# R7FA2L1AB register map
Vendor: Renesas Electronics Corporation; Series: RA2L1; File version: 1.60.00
CPU: CM23 r1p0, little endian, MPU, no FPU, VTOR, 2 interrupt priority bits, 32 interrupts
Registers are 8-bit, read-write, reset 0x0 unless marked. A register's access mark holds for its fields unless they carry their own. Offsets are from the block's base; [hi:lo] are bit positions; {n}, {i} and the like mark numbered series; 'fields as' and 'values as' point back to an identical list; <NAME> marks a mode.

## GPT320 — General PWM 32-bit Timer 0
Base 0x40078000
Same registers: GPT321 0x40078100, GPT322 0x40078200, GPT323 0x40078300
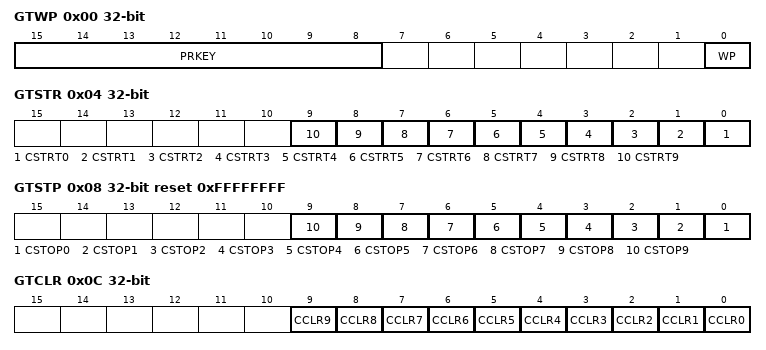
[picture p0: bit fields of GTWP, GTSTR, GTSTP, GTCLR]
0x00 GTWP 32-bit — General PWM Timer Write-Protection Register
  [15:8] PRKEY wo — GTWP Key Code
  [0] WP — Register Write Disable
    0=Write to the register enabled; 1=Write to the register disabled
0x04 GTSTR 32-bit — General PWM Timer Software Start Register
  [all] fields
    0=GTCNT counter not start; 1=GTCNT counter start
  [n] CSTRT{n} (n=0..9) — Channel n GTCNT Count Start (n : the same as bit position value)
0x08 GTSTP 32-bit reset 0xFFFFFFFF — General PWM Timer Software Stop Register
  [all] fields
    0=GTCNT counter not stop; 1=GTCNT counter stop
  [n] CSTOP{n} (n=0..9) — Channel n GTCNT Count Stop (n : the same as bit position value)
0x0C GTCLR 32-bit wo — General PWM Timer Software Clear Register
  [all] fields
    0=GTCNT counter is not cleared; 1=GTCNT counter is cleared
  [n] CCLR{n} (n=0..9) — Channel n GTCNT Count Clear (n : the same as bit position value)
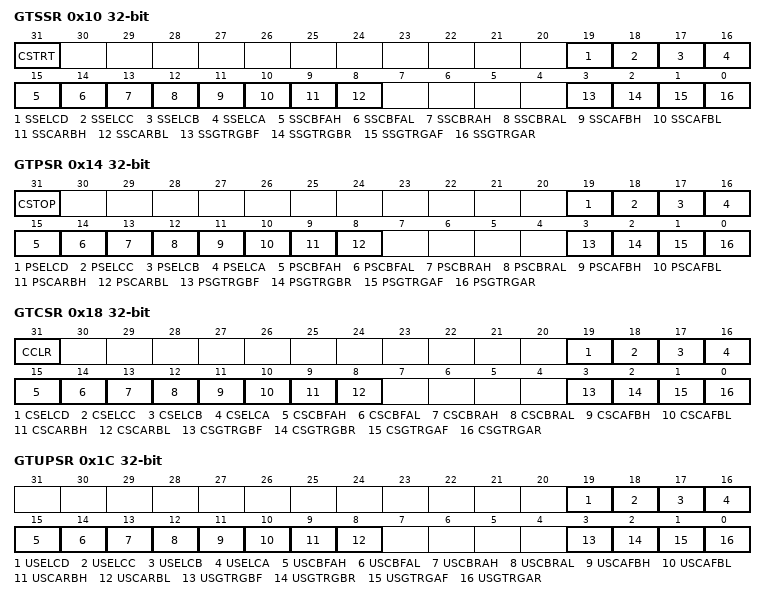
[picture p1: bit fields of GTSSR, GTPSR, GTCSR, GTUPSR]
0x10 GTSSR 32-bit — General PWM Timer Start Source Select Register
  [31] CSTRT — Software Source Counter Start Enable
    0=Counter start disabled by the GTSTR register; 1=Counter start enabled by the GTSTR register
  [19] SSELCD — ELC_GPTD Event Source Counter Start Enable
    0=Counter start disabled at the ELC_GPTD input; 1=Counter start enabled at the ELC_GPTD input
  [18] SSELCC — ELC_GPTC Event Source Counter Start Enable
    0=Counter start disabled at the ELC_GPTC input; 1=Counter start enabled at the ELC_GPTC input
  [17] SSELCB — ELC_GPTB Event Source Counter Start Enable
    0=Counter start disabled at the ELC_GPTB input; 1=Counter start enabled at the ELC_GPTB input
  [16] SSELCA — ELC_GPTA Event Source Counter Start Enable
    0=Counter start disabled at the ELC_GPTA input; 1=Counter start enabled at the ELC_GPTA input
  [15] SSCBFAH — GTIOCnB Pin Falling Input during GTIOCnA Value High Source Counter Start Enable
    0=Counter start disabled on the falling edge of GTIOCnB input when GTIOCnA input is 1; 1=Counter start enabled on the falling edge of GTIOCnB input when GTIOCnA input is 1
  [14] SSCBFAL — GTIOCnB Pin Falling Input during GTIOCnA Value Low Source Counter Start Enable
    0=Counter start disabled on the falling edge of GTIOCnB input when GTIOCnA input is 0; 1=Counter start enabled on the falling edge of GTIOCnB input when GTIOCnA input is 0
  [13] SSCBRAH — GTIOCnB Pin Rising Input during GTIOCnA Value High Source Counter Start Enable
    0=Counter start disabled on the rising edge of GTIOCnB input when GTIOCnA input is 1; 1=Counter start enabled on the rising edge of GTIOCnB input when GTIOCnA input is 1
  [12] SSCBRAL — GTIOCnB Pin Rising Input during GTIOCnA Value Low Source Counter Start Enable
    0=Counter start disabled on the rising edge of GTIOCnB input when GTIOCnA input is 0; 1=Counter start enabled on the rising edge of GTIOCnB input when GTIOCnA input is 0
  [11] SSCAFBH — GTIOCnA Pin Falling Input during GTIOCnB Value High Source Counter Start Enable
    0=Counter start disabled on the falling edge of GTIOCnA input when GTIOCnB input is 1; 1=Counter start enabled on the falling edge of GTIOCnA input when GTIOCnB input is 1
  [10] SSCAFBL — GTIOCnA Pin Falling Input during GTIOCnB Value Low Source Counter Start Enable
    0=Counter start disabled on the falling edge of GTIOCnA input when GTIOCnB input is 0; 1=Counter start enabled on the falling edge of GTIOCnA input when GTIOCnB input is 0
  [9] SSCARBH — GTIOCnA Pin Rising Input during GTIOCnB Value High Source Counter Start Enable
    0=Counter start disabled on the rising edge of GTIOCnA input when GTIOCnB input is 1; 1=Counter start enabled on the rising edge of GTIOCnA input when GTIOCnB input is 1
  [8] SSCARBL — GTIOCnA Pin Rising Input during GTIOCnB Value Low Source Counter Start Enable
    0=Counter start disabled on the rising edge of GTIOCnA input when GTIOCnB input is 0; 1=Counter start enabled on the rising edge of GTIOCnA input when GTIOCnB input is 0
  [3] SSGTRGBF — GTETRGB Pin Falling Input Source Counter Start Enable
    0=Counter start disabled on the falling edge of GTETRGB input; 1=Counter start enabled on the falling edge of GTETRGB input
  [2] SSGTRGBR — GTETRGB Pin Rising Input Source Counter Start Enable
    0=Counter start disabled on the rising edge of GTETRGB input; 1=Counter start enabled on the rising edge of GTETRGB input
  [1] SSGTRGAF — GTETRGA Pin Falling Input Source Counter Start Enable
    0=Counter start disabled on the falling edge of GTETRGA input; 1=Counter start enabled on the falling edge of GTETRGA input
  [0] SSGTRGAR — GTETRGA Pin Rising Input Source Counter Start Enable
    0=Counter start disabled on the rising edge of GTETRGA input; 1=Counter start enabled on the rising edge of GTETRGA input
0x14 GTPSR 32-bit — General PWM Timer Stop Source Select Register
  [31] CSTOP — Software Source Counter Stop Enable
    0=Counter stop disabled by the GTSTP register; 1=Counter stop enabled by the GTSTP register
  [19] PSELCD — ELC_GPTD Event Source Counter Stop Enable
    0=Counter stop disabled at the ELC_GPTD input; 1=Counter stop enabled at the ELC_GPTD input
  [18] PSELCC — ELC_GPTC Event Source Counter Stop Enable
    0=Counter stop disabled at the ELC_GPTC input; 1=Counter stop enabled at the ELC_GPTC input
  [17] PSELCB — ELC_GPTB Event Source Counter Stop Enable
    0=Counter stop disabled at the ELC_GPTB input; 1=Counter stop enabled at the ELC_GPTB input
  [16] PSELCA — ELC_GPTA Event Source Counter Stop Enable
    0=Counter stop disabled at the ELC_GPTA input; 1=Counter stop enabled at the ELC_GPTA input
  [15] PSCBFAH — GTIOCnB Pin Falling Input during GTIOCnA Value High Source Counter Stop Enable
    0=Counter stop disabled on the falling edge of GTIOCnB input when GTIOCnA input is 1; 1=Counter stop enabled on the falling edge of GTIOCnB input when GTIOCnA input is 1
  [14] PSCBFAL — GTIOCnB Pin Falling Input during GTIOCnA Value Low Source Counter Stop Enable
    0=Counter stop disabled on the falling edge of GTIOCnB input when GTIOCnA input is 0; 1=Counter stop enabled on the falling edge of GTIOCnB input when GTIOCnA input is 0
  [13] PSCBRAH — GTIOCnB Pin Rising Input during GTIOCnA Value High Source Counter Stop Enable
    0=Counter stop disabled on the rising edge of GTIOCnB input when GTIOCnA input is 1; 1=Counter stop enabled on the rising edge of GTIOCnB input when GTIOCnA input is 1
  [12] PSCBRAL — GTIOCnB Pin Rising Input during GTIOCnA Value Low Source Counter Stop Enable
    0=Counter stop disabled on the rising edge of GTIOCnB input when GTIOCnA input is 0; 1=Counter stop enabled on the rising edge of GTIOCnB input when GTIOCnA input is 0
  [11] PSCAFBH — GTIOCnA Pin Falling Input during GTIOCnB Value High Source Counter Stop Enable
    0=Counter stop disabled on the falling edge of GTIOCnA input when GTIOCnB input is 1; 1=Counter stop enabled on the falling edge of GTIOCnA input when GTIOCnB input is 1
  [10] PSCAFBL — GTIOCnA Pin Falling Input during GTIOCnB Value Low Source Counter Stop Enable
    0=Counter stop disabled on the falling edge of GTIOCnA input when GTIOCnB input is 0; 1=Counter stop enabled on the falling edge of GTIOCnA input when GTIOCnB input is 0
  [9] PSCARBH — GTIOCnA Pin Rising Input during GTIOCnB Value High Source Counter Stop Enable
    0=Counter stop disabled on the rising edge of GTIOCnA input when GTIOCnB input is 1; 1=Counter stop enabled on the rising edge of GTIOCnA input when GTIOCnB input is 1
  [8] PSCARBL — GTIOCnA Pin Rising Input during GTIOCnB Value Low Source Counter Stop Enable
    0=Counter stop disabled on the rising edge of GTIOCnA input when GTIOCnB input is 0; 1=Counter stop enabled on the rising edge of GTIOCnA input when GTIOCnB input is 0
  [3] PSGTRGBF — GTETRGB Pin Falling Input Source Counter Stop Enable
    0=Counter stop disabled on the falling edge of GTETRGB input; 1=Counter stop enabled on the falling edge of GTETRGB input
  [2] PSGTRGBR — GTETRGB Pin Rising Input Source Counter Stop Enable
    0=Counter stop disabled on the rising edge of GTETRGB input; 1=Counter stop enabled on the rising edge of GTETRGB input
  [1] PSGTRGAF — GTETRGA Pin Falling Input Source Counter Stop Enable
    0=Counter stop disabled on the falling edge of GTETRGA input; 1=Counter stop enabled on the falling edge of GTETRGA input
  [0] PSGTRGAR — GTETRGA Pin Rising Input Source Counter Stop Enable
    0=Counter stop disabled on the rising edge of GTETRGA input; 1=Counter stop enabled on the rising edge of GTETRGA input
0x18 GTCSR 32-bit — General PWM Timer Clear Source Select Register
  [31] CCLR — Software Source Counter Clear Enable
    0=Counter clear disabled by the GTCLR register; 1=Counter clear enabled by the GTCLR register
  [19] CSELCD — ELC_GPTD Event Source Counter Clear Enable
    0=Counter clear disabled at the ELC_GPTD input; 1=Counter clear enabled at the ELC_GPTD input
  [18] CSELCC — ELC_GPTC Event Source Counter Clear Enable
    0=Counter clear disabled at the ELC_GPTC input; 1=Counter clear enabled at the ELC_GPTC input
  [17] CSELCB — ELC_GPTB Event Source Counter Clear Enable
    0=Counter clear disabled at the ELC_GPTB input; 1=Counter clear enabled at the ELC_GPTB input
  [16] CSELCA — ELC_GPTA Event Source Counter Clear Enable
    0=Counter clear disabled at the ELC_GPTA input; 1=Counter clear enabled at the ELC_GPTA input
  [15] CSCBFAH — GTIOCnB Pin Falling Input during GTIOCnA Value High Source Counter Clear Enable
    0=Counter clear disabled on the falling edge of GTIOCnB input when GTIOCnA input is 1; 1=Counter clear enabled on the falling edge of GTIOCnB input when GTIOCnA input is 1
  [14] CSCBFAL — GTIOCnB Pin Falling Input during GTIOCnA Value Low Source Counter Clear Enable
    0=Counter clear disabled on the falling edge of GTIOCnB input when GTIOCnA input is 0; 1=Counter clear enabled on the falling edge of GTIOCnB input when GTIOCnA input is 0
  [13] CSCBRAH — GTIOCnB Pin Rising Input during GTIOCnA Value High Source Counter Clear Enable
    0=Counter clear disabled on the rising edge of GTIOCnB input when GTIOCnA input is 1; 1=Counter clear enabled on the rising edge of GTIOCnB input when GTIOCnA input is 1
  [12] CSCBRAL — GTIOCnB Pin Rising Input during GTIOCnA Value Low Source Counter Clear Enable
    0=Counter clear disabled on the rising edge of GTIOCnB input when GTIOCnA input is 0; 1=Counter clear enabled on the rising edge of GTIOCnB input when GTIOCnA input is 0
  [11] CSCAFBH — GTIOCnA Pin Falling Input during GTIOCnB Value High Source Counter Clear Enable
    0=Counter clear disabled on the falling edge of GTIOCnA input when GTIOCnB input is 1; 1=Counter clear enabled on the falling edge of GTIOCnA input when GTIOCnB input is 1
  [10] CSCAFBL — GTIOCnA Pin Falling Input during GTIOCnB Value Low Source Counter Clear Enable
    0=Counter clear disabled on the falling edge of GTIOCnA input when GTIOCnB input is 0; 1=Counter clear enabled on the falling edge of GTIOCnA input when GTIOCnB input is 0
  [9] CSCARBH — GTIOCnA Pin Rising Input during GTIOCnB Value High Source Counter Clear Enable
    0=Counter clear disabled on the rising edge of GTIOCnA input when GTIOCnB input is 1; 1=Counter clear enabled on the rising edge of GTIOCnA input when GTIOCnB input is 1
  [8] CSCARBL — GTIOCnA Pin Rising Input during GTIOCnB Value Low Source Counter Clear Enable
    0=Counter clear disabled on the rising edge of GTIOCnA input when GTIOCnB input is 0; 1=Counter clear enabled on the rising edge of GTIOCnA input when GTIOCnB input is 0
  [3] CSGTRGBF — GTETRGB Pin Falling Input Source Counter Clear Enable
    0=Counter clear disabled on the falling edge of GTETRGB input; 1=Counter clear enabled on the falling edge of GTETRGB input
  [2] CSGTRGBR — GTETRGB Pin Rising Input Source Counter Clear Enable
    0=Disable counter clear on the rising edge of GTETRGB input; 1=Enable counter clear on the rising edge of GTETRGB input
  [1] CSGTRGAF — GTETRGA Pin Falling Input Source Counter Clear Enable
    0=Counter clear disabled on the falling edge of GTETRGA input; 1=Counter clear enabled on the falling edge of GTETRGA input
  [0] CSGTRGAR — GTETRGA Pin Rising Input Source Counter Clear Enable
    0=Counter clear disabled on the rising edge of GTETRGA input; 1=Counter clear enabled on the rising edge of GTETRGA input
0x1C GTUPSR 32-bit — General PWM Timer Up Count Source Select Register
  [19] USELCD — ELC_GPTD Event Source Counter Count Up Enable
    0=Counter count up disabled at the ELC_GPTD input; 1=Counter count up enabled at the ELC_GPTD input
  [18] USELCC — ELC_GPTC Event Source Counter Count Up Enable
    0=Counter count up disabled at the ELC_GPTC input; 1=Counter count up enabled at the ELC_GPTC input
  [17] USELCB — ELC_GPTB Event Source Counter Count Up Enable
    0=Counter count up disabled at the ELC_GPTB input; 1=Counter count up enabled at the ELC_GPTB input
  [16] USELCA — ELC_GPTA Event Source Counter Count Up Enable
    0=Counter count up disabled at the ELC_GPTA input; 1=Counter count up enabled at the ELC_GPTA input
  [15] USCBFAH — GTIOCnB Pin Falling Input during GTIOCnA Value High Source Counter Count Up Enable
    0=Counter count up disabled on the falling edge of GTIOCnB input when GTIOCnA input is 1; 1=Counter count up enabled on the falling edge of GTIOCnB input when GTIOCnA input is 1
  [14] USCBFAL — GTIOCnB Pin Falling Input during GTIOCnA Value Low Source Counter Count Up Enable
    0=Counter count up disabled on the falling edge of GTIOCnB input when GTIOCnA input is 0; 1=Counter count up enabled on the falling edge of GTIOCnB input when GTIOCnA input is 0
  [13] USCBRAH — GTIOCnB Pin Rising Input during GTIOCnA Value High Source Counter Count Up Enable
    0=Counter count up disabled on the rising edge of GTIOCnB input when GTIOCnA input is 1; 1=Counter count up enabled on the rising edge of GTIOCnB input when GTIOCnA input is 1
  [12] USCBRAL — GTIOCnB Pin Rising Input during GTIOCnA Value Low Source Counter Count Up Enable
    0=Counter count up disabled on the rising edge of GTIOCnB input when GTIOCnA input is 0; 1=Counter count up enabled on the rising edge of GTIOCnB input when GTIOCnA input is 0
  [11] USCAFBH — GTIOCnA Pin Falling Input during GTIOCnB Value High Source Counter Count Up Enable
    0=Counter count up disabled on the falling edge of GTIOCnA input when GTIOCnB input is 1; 1=Counter count up enabled on the falling edge of GTIOCnA input when GTIOCnB input is 1
  [10] USCAFBL — GTIOCnA Pin Falling Input during GTIOCnB Value Low Source Counter Count Up Enable
    0=Counter count up disabled on the falling edge of GTIOCnA input when GTIOCnB input is 0; 1=Counter count up enabled on the falling edge of GTIOCnA input when GTIOCnB input is 0
  [9] USCARBH — GTIOCnA Pin Rising Input during GTIOCnB Value High Source Counter Count Up Enable
    0=Counter count up disabled on the rising edge of GTIOCnA input when GTIOCnB input is 1; 1=Counter count up enabled on the rising edge of GTIOCnA input when GTIOCnB input is 1
  [8] USCARBL — GTIOCnA Pin Rising Input during GTIOCnB Value Low Source Counter Count Up Enable
    0=Counter count up disabled on the rising edge of GTIOCnA input when GTIOCnB input is 0; 1=Counter count up enabled on the rising edge of GTIOCnA input when GTIOCnB input is 0
  [3] USGTRGBF — GTETRGB Pin Falling Input Source Counter Count Up Enable
    0=Counter count up disabled on the falling edge of GTETRGB input; 1=Counter count up enabled on the falling edge of GTETRGB input
  [2] USGTRGBR — GTETRGB Pin Rising Input Source Counter Count Up Enable
    0=Counter count up disabled on the rising edge of GTETRGB input; 1=Counter count up enabled on the rising edge of GTETRGB input
  [1] USGTRGAF — GTETRGA Pin Falling Input Source Counter Count Up Enable
    0=Counter count up disabled on the falling edge of GTETRGA input; 1=Counter count up enabled on the falling edge of GTETRGA input
  [0] USGTRGAR — GTETRGA Pin Rising Input Source Counter Count Up Enable
    0=Counter count up disabled on the rising edge of GTETRGA input; 1=Counter count up enabled on the rising edge of GTETRGA input
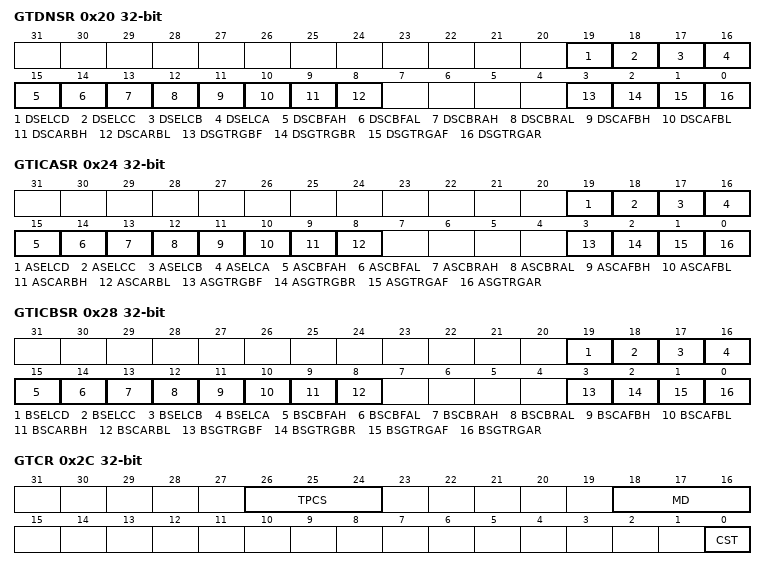
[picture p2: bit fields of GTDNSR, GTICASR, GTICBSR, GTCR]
0x20 GTDNSR 32-bit — General PWM Timer Down Count Source Select Register
  [19] DSELCD — ELC_GPTD Event Source Counter Count Down Enable
    0=Counter count down disabled at the ELC_GPTD input; 1=Counter count down enabled at the ELC_GPTD input
  [18] DSELCC — ELC_GPTC Event Source Counter Count Down Enable
    0=Counter count down disabled at the ELC_GPTC input; 1=Counter count down enabled at the ELC_GPTC input
  [17] DSELCB — ELC_GPTB Event Source Counter Count Down Enable
    0=Counter count down disabled at the ELC_GPTB input; 1=Counter count down enabled at the ELC_GPTB input
  [16] DSELCA — ELC_GPTA Event Source Counter Count Down Enable
    0=Counter count down disabled at the ELC_GPTA input; 1=Counter count down enabled at the ELC_GPTA input
  [15] DSCBFAH — GTIOCnB Pin Falling Input during GTIOCnA Value High Source Counter Count Down Enable
    0=Counter count down disabled on the falling edge of GTIOCnB input when GTIOCnA input is 1; 1=Counter count down enabled on the falling edge of GTIOCnB input when GTIOCnA input is 1
  [14] DSCBFAL — GTIOCnB Pin Falling Input during GTIOCnA Value Low Source Counter Count Down Enable
    0=Counter count down disabled on the falling edge of GTIOCnB input when GTIOCnA input is 0; 1=Counter count down enabled on the falling edge of GTIOCnB input when GTIOCnA input is 0
  [13] DSCBRAH — GTIOCnB Pin Rising Input during GTIOCnA Value High Source Counter Count Down Enable
    0=Counter count down disabled on the rising edge of GTIOCnB input when GTIOCnA input is 1; 1=Counter count down enabled on the rising edge of GTIOCnB input when GTIOCnA input is 1
  [12] DSCBRAL — GTIOCnB Pin Rising Input during GTIOCnA Value Low Source Counter Count Down Enable
    0=Counter count down disabled on the rising edge of GTIOCnB input when GTIOCnA input is 0; 1=Counter count down enabled on the rising edge of GTIOCnB input when GTIOCnA input is 0
  [11] DSCAFBH — GTIOCnA Pin Falling Input during GTIOCnB Value High Source Counter Count Down Enable
    0=Counter count down disabled on the falling edge of GTIOCnA input when GTIOCnB input is 1; 1=Counter count down enabled on the falling edge of GTIOCnA input when GTIOCnB input is 1
  [10] DSCAFBL — GTIOCnA Pin Falling Input during GTIOCnB Value Low Source Counter Count Down Enable
    0=Counter count down disabled on the falling edge of GTIOCnA input when GTIOCnB input is 0; 1=Counter count down enabled on the falling edge of GTIOCnA input when GTIOCnB input is 0
  [9] DSCARBH — GTIOCnA Pin Rising Input during GTIOCnB Value High Source Counter Count Down Enable
    0=Counter count down disabled on the rising edge of GTIOCnA input when GTIOCnB input is 1; 1=Counter count down enabled on the rising edge of GTIOCnA input when GTIOCnB input is 1
  [8] DSCARBL — GTIOCnA Pin Rising Input during GTIOCnB Value Low Source Counter Count Down Enable
    0=Counter count down disabled on the rising edge of GTIOCnA input when GTIOCnB input is 0; 1=Counter count down enabled on the rising edge of GTIOCnA input when GTIOCnB input is 0
  [3] DSGTRGBF — GTETRGB Pin Falling Input Source Counter Count Down Enable
    0=Counter count down disabled on the falling edge of GTETRGB input; 1=Counter count down enabled on the falling edge of GTETRGB input
  [2] DSGTRGBR — GTETRGB Pin Rising Input Source Counter Count Down Enable
    0=Counter count down disabled on the rising edge of GTETRGB input; 1=Counter count down enabled on the rising edge of GTETRGB input
  [1] DSGTRGAF — GTETRGA Pin Falling Input Source Counter Count Down Enable
    0=Counter count down disabled on the falling edge of GTETRGA input; 1=Counter count down enabled on the falling edge of GTETRGA input
  [0] DSGTRGAR — GTETRGA Pin Rising Input Source Counter Count Down Enable
    0=Counter count down disabled on the rising edge of GTETRGA input; 1=Counter count down enabled on the rising edge of GTETRGA input
0x24 GTICASR 32-bit — General PWM Timer Input Capture Source Select Register A
  [19] ASELCD — ELC_GPTD Event Source GTCCRA Input Capture Enable
    0=GTCCRA input capture disabled at the ELC_GPTD input; 1=GTCCRA input capture enabled at the ELC_GPTD input
  [18] ASELCC — ELC_GPTC Event Source GTCCRA Input Capture Enable
    0=GTCCRA input capture disabled at the ELC_GPTC input; 1=GTCCRA input capture enabled at the ELC_GPTC input
  [17] ASELCB — ELC_GPTB Event Source GTCCRA Input Capture Enable
    0=GTCCRA input capture disabled at the ELC_GPTB input; 1=GTCCRA input capture enabled at the ELC_GPTB input
  [16] ASELCA — ELC_GPTA Event Source GTCCRA Input Capture Enable
    0=GTCCRA input capture disabled at the ELC_GPTA input; 1=GTCCRA input capture enabled at the ELC_GPTA input
  [15] ASCBFAH — GTIOCnB Pin Falling Input during GTIOCnA Value High Source GTCCRA Input Capture Enable
    0=GTCCRA input capture disabled on the falling edge of GTIOCnB input when GTIOCnA input is 1; 1=GTCCRA input capture enabled on the falling edge of GTIOCnB input when GTIOCnA input is 1
  [14] ASCBFAL — GTIOCnB Pin Falling Input during GTIOCnA Value Low Source GTCCRA Input Capture Enable
    0=GTCCRA input capture disabled on the falling edge of GTIOCnB input when GTIOCnA input is 0; 1=GTCCRA input capture enabled on the falling edge of GTIOCnB input when GTIOCnA input is 0
  [13] ASCBRAH — GTIOCnB Pin Rising Input during GTIOCnA Value High Source GTCCRA Input Capture Enable
    0=GTCCRA input capture disabled on the rising edge of GTIOCnB input when GTIOCnA input is 1; 1=GTCCRA input capture enabled on the rising edge of GTIOCnB input when GTIOCnA input is 1
  [12] ASCBRAL — GTIOCnB Pin Rising Input during GTIOCnA Value Low Source GTCCRA Input Capture Enable
    0=GTCCRA input capture disabled on the rising edge of GTIOCnB input when GTIOCnA input is 0; 1=GTCCRA input capture enabled on the rising edge of GTIOCnB input when GTIOCnA input is 0
  [11] ASCAFBH — GTIOCnA Pin Falling Input during GTIOCnB Value High Source GTCCRA Input Capture Enable
    0=GTCCRA input capture disabled on the falling edge of GTIOCnA input when GTIOCnB input is 1; 1=GTCCRA input capture enabled on the falling edge of GTIOCnA input when GTIOCnB input is 1
  [10] ASCAFBL — GTIOCnA Pin Falling Input during GTIOCnB Value Low Source GTCCRA Input Capture Enable
    0=GTCCRA input capture disabled on the falling edge of GTIOCnA input when GTIOCnB input is 0; 1=GTCCRA input capture enabled on the falling edge of GTIOCnA input when GTIOCnB input is 0
  [9] ASCARBH — GTIOCnA Pin Rising Input during GTIOCnB Value High Source GTCCRA Input Capture Enable
    0=GTCCRA input capture disabled on the rising edge of GTIOCnA input when GTIOCnB input is 1; 1=GTCCRA input capture enabled on the rising edge of GTIOCnA input when GTIOCnB input is 1
  [8] ASCARBL — GTIOCnA Pin Rising Input during GTIOCnB Value Low Source GTCCRA Input Capture Enable
    0=GTCCRA input capture disabled on the rising edge of GTIOCnA input when GTIOCnB input is 0; 1=GTCCRA input capture enabled on the rising edge of GTIOCnA input when GTIOCnB input is 0
  [3] ASGTRGBF — GTETRGB Pin Falling Input Source GTCCRA Input Capture Enable
    0=GTCCRA input capture disabled on the falling edge of GTETRGB input; 1=GTCCRA input capture enabled on the falling edge of GTETRGB input
  [2] ASGTRGBR — GTETRGB Pin Rising Input Source GTCCRA Input Capture Enable
    0=GTCCRA input capture disabled on the rising edge of GTETRGB input; 1=GTCCRA input capture enabled on the rising edge of GTETRGB input
  [1] ASGTRGAF — GTETRGA Pin Falling Input Source GTCCRA Input Capture Enable
    0=GTCCRA input capture disabled on the falling edge of GTETRGA input; 1=GTCCRA input capture enabled on the falling edge of GTETRGA input
  [0] ASGTRGAR — GTETRGA Pin Rising Input Source GTCCRA Input Capture Enable
    0=GTCCRA input capture disabled on the rising edge of GTETRGA input; 1=GTCCRA input capture enabled on the rising edge of GTETRGA input
0x28 GTICBSR 32-bit — General PWM Timer Input Capture Source Select Register B
  [19] BSELCD — ELC_GPTD Event Source GTCCRB Input Capture Enable
    0=GTCCRB input capture disabled at the ELC_GPTD input; 1=GTCCRB input capture enabled at the ELC_GPTD input
  [18] BSELCC — ELC_GPTC Event Source GTCCRB Input Capture Enable
    0=GTCCRB input capture disabled at the ELC_GPTC input; 1=GTCCRB input capture enabled at the ELC_GPTC input
  [17] BSELCB — ELC_GPTB Event Source GTCCRB Input Capture Enable
    0=GTCCRB input capture disabled at the ELC_GPTB input; 1=GTCCRB input capture enabled at the ELC_GPTB input
  [16] BSELCA — ELC_GPTA Event Source GTCCRB Input Capture Enable
    0=GTCCRB input capture disabled at the ELC_GPTA input; 1=GTCCRB input capture enabled at the ELC_GPTA input
  [15] BSCBFAH — GTIOCnB Pin Falling Input during GTIOCnA Value High Source GTCCRB Input Capture Enable
    0=GTCCRB input capture disabled on the falling edge of GTIOCnB input when GTIOCnA input is 1; 1=GTCCRB input capture enabled on the falling edge of GTIOCnB input when GTIOCnA input is 1
  [14] BSCBFAL — GTIOCnB Pin Falling Input during GTIOCnA Value Low Source GTCCRB Input Capture Enable
    0=GTCCRB input capture disabled on the falling edge of GTIOCnB input when GTIOCnA input is 0; 1=GTCCRB input capture enabled on the falling edge of GTIOCnB input when GTIOCnA input is 0
  [13] BSCBRAH — GTIOCnB Pin Rising Input during GTIOCnA Value High Source GTCCRB Input Capture Enable
    0=GTCCRB input capture disabled on the rising edge of GTIOCnB input when GTIOCnA input is 1; 1=GTCCRB input capture enabled on the rising edge of GTIOCnB input when GTIOCnA input is 1
  [12] BSCBRAL — GTIOCnB Pin Rising Input during GTIOCnA Value Low Source GTCCRB Input Capture Enable
    0=GTCCRB input capture disabled on the rising edge of GTIOCnB input when GTIOCnA input is 0; 1=GTCCRB input capture enabled on the rising edge of GTIOCnB input when GTIOCnA input is 0
  [11] BSCAFBH — GTIOCnA Pin Falling Input during GTIOCnB Value High Source GTCCRB Input Capture Enable
    0=GTCCRB input capture disabled on the falling edge of GTIOCnA input when GTIOCnB input is 1; 1=GTCCRB input capture enabled on the falling edge of GTIOCnA input when GTIOCnB input is 1
  [10] BSCAFBL — GTIOCnA Pin Falling Input during GTIOCnB Value Low Source GTCCRB Input Capture Enable
    0=GTCCRB input capture disabled on the falling edge of GTIOCnA input when GTIOCnB input is 0; 1=GTCCRB input capture enabled on the falling edge of GTIOCnA input when GTIOCnB input is 0
  [9] BSCARBH — GTIOCnA Pin Rising Input during GTIOCnB Value High Source GTCCRB Input Capture Enable
    0=GTCCRB input capture disabled on the rising edge of GTIOCnA input when GTIOCnB input is 1; 1=GTCCRB input capture enabled on the rising edge of GTIOCnA input when GTIOCnB input is 1
  [8] BSCARBL — GTIOCnA Pin Rising Input during GTIOCnB Value Low Source GTCCRB Input Capture Enable
    0=GTCCRB input capture disabled on the rising edge of GTIOCnA input when GTIOCnB input is 0; 1=GTCCRB input capture enabled on the rising edge of GTIOCnA input when GTIOCnB input is 0
  [3] BSGTRGBF — GTETRGB Pin Falling Input Source GTCCRB Input Capture Enable
    0=GTCCRB input capture disabled on the falling edge of GTETRGB input; 1=GTCCRB input capture enabled on the falling edge of GTETRGB input
  [2] BSGTRGBR — GTETRGB Pin Rising Input Source GTCCRB Input Capture Enable
    0=GTCCRB input capture disabled on the rising edge of GTETRGB input; 1=GTCCRB input capture enabled on the rising edge of GTETRGB input
  [1] BSGTRGAF — GTETRGA Pin Falling Input Source GTCCRB Input Capture Enable
    0=GTCCRB input capture disabled on the falling edge of GTETRGA input; 1=GTCCRB input capture enabled on the falling edge of GTETRGA input
  [0] BSGTRGAR — GTETRGA Pin Rising Input Source GTCCRB Input Capture Enable
    0=GTCCRB input capture disabled on the rising edge of GTETRGA input; 1=GTCCRB input capture enabled on the rising edge of GTETRGA input
0x2C GTCR 32-bit — General PWM Timer Control Register
  [26:24] TPCS — Timer Prescaler Select
    0=PCLKD/1; 1=PCLKD/4; 2=PCLKD/16; 3=PCLKD/64; 4=PCLKD/256; 5=PCLKD/1024; other=Others (Setting prohibited)
  [18:16] MD — Mode Select
    0=Saw-wave PWM mode (single buffer or double buffer possible); 1=Saw-wave one-shot pulse mode (fixed buffer operation); 2=Setting prohibited; 3=Setting prohibited; 4=Triangle-wave PWM mode 1 (32-bit transfer at trough) (single buffer or double buffer is possible); 5=Triangle-wave PWM mode 2 (32-bit transfer at crest and trough) (single buffer or double buffer is possible); 6=Triangle-wave PWM mode 3 (64-bit transfer at trough) (fixed buffer operation); 7=Setting prohibited
  [0] CST — Count Start
    0=Count operation is stopped; 1=Count operation is performed
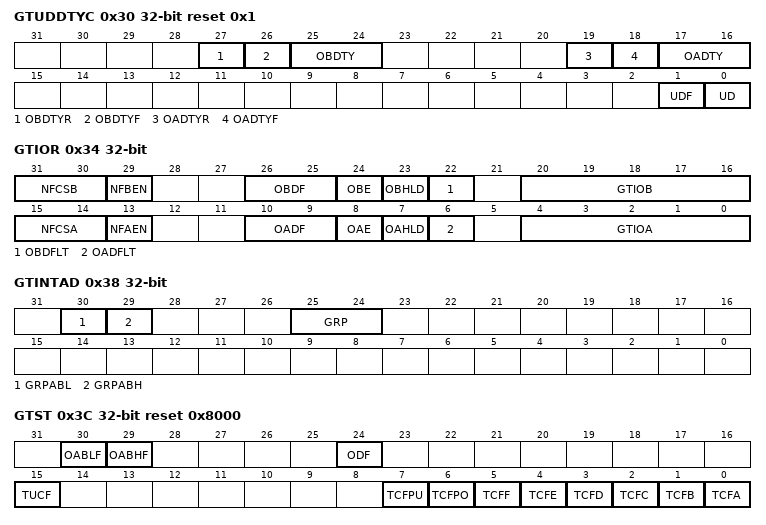
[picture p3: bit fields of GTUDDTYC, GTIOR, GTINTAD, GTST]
0x30 GTUDDTYC 32-bit reset 0x1 — General PWM Timer Count Direction and Duty Setting Register
  [27] OBDTYR — GTIOCnB Output Value Selecting after Releasing 0%/100% Duty Setting
    0=The function selected by the GTIOB[3:2] bits is applied to the output value when the duty cycle is set after release from the 0 or 100% duty-cycle setting; 1=The function selected by the GTIOB[3:2] bits is applied to the compare match output value which is masked after release from the 0 or 100% duty-cycle setting
  [26] OBDTYF — Forcible GTIOCnB Output Duty Setting
    0=Not forcibly set; 1=Forcibly set
  [25:24] OBDTY — GTIOCnB Output Duty Setting
    0=GTIOCnB pin duty depends on the compare match; 1=GTIOCnB pin duty depends on the compare match; 2=GTIOCnB pin duty 0%; 3=GTIOCnB pin duty 100%
  [19] OADTYR — GTIOCnA Output Value Selecting after Releasing 0%/100% Duty Setting
    0=The function selected by the GTIOA[3:2] bits is applied to the output value when the duty cycle is set after release from the 0 or 100% duty-cycle setting; 1=The function selected by the GTIOA[3:2] bits is applied to the compare match output value which is masked after release from the 0 or 100% duty-cycle setting
  [18] OADTYF — Forcible GTIOCnA Output Duty Setting
    0=Not forcibly set; 1=Forcibly set
  [17:16] OADTY — GTIOCnA Output Duty Setting
    0=GTIOCnA pin duty depends on the compare match; 1=GTIOCnA pin duty depends on the compare match; 2=GTIOCnA pin duty 0%; 3=GTIOCnA pin duty 100%
  [1] UDF — Forcible Count Direction Setting
    0=Not forcibly set; 1=Forcibly set
  [0] UD — Count Direction Setting
    0=GTCNT counts down; 1=GTCNT counts up
0x34 GTIOR 32-bit — General PWM Timer I/O Control Register
  [31:30] NFCSB — Noise Filter B Sampling Clock Select
    0=PCLKD/1; 1=PCLKD/4; 2=PCLKD/16; 3=PCLKD/64
  [29] NFBEN — Noise Filter B Enable
    0=The noise filter for the GTIOCnB pin is disabled; 1=The noise filter for the GTIOCnB pin is enabled
  [26:25] OBDF — GTIOCnB Pin Disable Value Setting
    0=None of the below options are specified; 1=GTIOCnB pin is set to Hi-Z in response to controlling the output negation; 2=GTIOCnB pin is set to 0 in response to controlling the output negation; 3=GTIOCnB pin is set to 1 in response to controlling the output negation
  [24] OBE — GTIOCnB Pin Output Enable
    0=Output is disabled; 1=Output is enabled
  [23] OBHLD — GTIOCnB Pin Output Setting at the Start/Stop Count
    0=The GTIOCnB pin output level at the start/stop of counting depends on the register setting; 1=The GTIOCnB pin output level is retained at the start/stop of counting
  [22] OBDFLT — GTIOCnB Pin Output Value Setting at the Count Stop
    0=The GTIOCnB pin outputs low when counting stops; 1=The GTIOCnB pin outputs high when counting stops
  [20:16] GTIOB — GTIOCnB Pin Function Select
  [15:14] NFCSA — Noise Filter A Sampling Clock Select
    0=PCLKD/1; 1=PCLKD/4; 2=PCLKD/16; 3=PCLKD/64
  [13] NFAEN — Noise Filter A Enable
    0=The noise filter for the GTIOCnA pin is disabled; 1=The noise filter for the GTIOCnA pin is enabled
  [10:9] OADF — GTIOCnA Pin Disable Value Setting
    0=None of the below options are specified; 1=GTIOCnA pin is set to Hi-Z in response to controlling the output negation; 2=GTIOCnA pin is set to 0 in response to controlling the output negation; 3=GTIOCnA pin is set to 1 in response to controlling the output negation
  [8] OAE — GTIOCnA Pin Output Enable
    0=Output is disabled; 1=Output is enabled
  [7] OAHLD — GTIOCnA Pin Output Setting at the Start/Stop Count
    0=The GTIOCnA pin output level at the start or stop of counting depends on the register setting; 1=The GTIOCnA pin output level is retained at the start or stop of counting
  [6] OADFLT — GTIOCnA Pin Output Value Setting at the Count Stop
    0=The GTIOCnA pin outputs low when counting stops; 1=The GTIOCnA pin outputs high when counting stops
  [4:0] GTIOA — GTIOCnA Pin Function Select
0x38 GTINTAD 32-bit — General PWM Timer Interrupt Output Setting Register
  [30] GRPABL — Same Time Output Level Low Disable Request Enable
    0=Same time output level low disable request disabled; 1=Same time output level low disable request enabled
  [29] GRPABH — Same Time Output Level High Disable Request Enable
    0=Same time output level high disable request disabled; 1=Same time output level high disable request enabled
  [25:24] GRP — Output Disable Source Select
    0=Group A output disable request is selected; 1=Group B output disable request is selected; other=Others (Setting prohibited)
0x3C GTST 32-bit reset 0x8000 — General PWM Timer Status Register
  [30] OABLF ro — Same Time Output Level Low Flag
    0=No simultaneous generation of 0 both for the GTIOCA and GTIOCB pins has occurred; 1=A simultaneous generation of 0 both for the GTIOCA and GTIOCB pins has occurred
  [29] OABHF ro — Same Time Output Level High Flag
    0=No simultaneous generation of 1 both for the GTIOCA and GTIOCB pins has occurred; 1=A simultaneous generation of 1 both for the GTIOCA and GTIOCB pins has occurred
  [24] ODF ro — Output Disable Flag
    0=No output disable request is generated; 1=An output disable request is generated
  [15] TUCF ro — Count Direction Flag
    0=GTCNT counter counts downward; 1=GTCNT counter counts upward
  [7] TCFPU — Underflow Flag
    0=No underflow (trough) occurred; 1=An underflow (trough) occurred
  [6] TCFPO — Overflow Flag
    0=No overflow (crest) occurred; 1=An overflow (crest) occurred
  [5] TCFF — Input Compare Match Flag F
    0=No compare match of GTCCRF is generated; 1=A compare match of GTCCRF is generated
  [4] TCFE — Input Compare Match Flag E
    0=No compare match of GTCCRE is generated; 1=A compare match of GTCCRE is generated
  [3] TCFD — Input Compare Match Flag D
    0=No compare match of GTCCRD is generated; 1=A compare match of GTCCRD is generated
  [2] TCFC — Input Compare Match Flag C
    0=No compare match of GTCCRC is generated; 1=A compare match of GTCCRC is generated
  [1] TCFB — Input Capture/Compare Match Flag B
    0=No input capture/compare match of GTCCRB is generated; 1=An input capture/compare match of GTCCRB is generated
  [0] TCFA — Input Capture/Compare Match Flag A
    0=No input capture/compare match of GTCCRA is generated; 1=An input capture/compare match of GTCCRA is generated
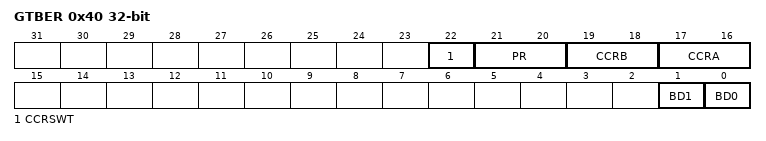
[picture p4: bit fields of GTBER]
0x40 GTBER 32-bit — General PWM Timer Buffer Enable Register
  [22] CCRSWT wo — GTCCRA and GTCCRB Forcible Buffer Operation
  [21:20] PR — GTPR Buffer Operation
    0=No buffer operation; 1=Single buffer operation (GTPBR --> GTPR); other=Others (Setting prohibited)
  [19:18] CCRB — GTCCRB Buffer Operation
    0=No buffer operation; 1=Single buffer operation (GTCCRB <----> GTCCRE); other=Others (Double buffer operation (GTCCRB <----> GTCCRE <----> GTCCRF))
  [17:16] CCRA — GTCCRA Buffer Operation
    0=No buffer operation; 1=Single buffer operation (GTCCRA <---->GTCCRC); other=Others (Double buffer operation (GTCCRA <----> GTCCRC <----> GTCCRD))
  [1] BD1 — GTPR Buffer Operation Disable
    0=Buffer operation is enabled; 1=Buffer operation is disabled
  [0] BD0 — GTCCR Buffer Operation Disable
    values as BD1
0x48 GTCNT 32-bit — General PWM Timer Counter
0x4C GTCCRA 32-bit reset 0xFFFFFFFF — General PWM Timer Compare Capture Register A
0x50 GTCCRB 32-bit reset 0xFFFFFFFF — General PWM Timer Compare Capture Register B
0x54 GTCCRC 32-bit reset 0xFFFFFFFF — General PWM Timer Compare Capture Register C
0x58 GTCCRE 32-bit reset 0xFFFFFFFF — General PWM Timer Compare Capture Register E
0x5C GTCCRD 32-bit reset 0xFFFFFFFF — General PWM Timer Compare Capture Register D
0x60 GTCCRF 32-bit reset 0xFFFFFFFF — General PWM Timer Compare Capture Register F
0x64 GTPR 32-bit reset 0xFFFFFFFF — General PWM Timer Cycle Setting Register
0x68 GTPBR 32-bit reset 0xFFFFFFFF — General PWM Timer Cycle Setting Buffer Register
0x88 GTDTCR 32-bit — General PWM Timer Dead Time Control Register
  [0] TDE — Negative-Phase Waveform Setting
    0=GTCCRB is set without using GTDVU; 1=GTDVU is used to set the compare match value for negative-phase waveform with dead time automatically in GTCCRB
0x8C GTDVU 32-bit reset 0xFFFFFFFF — General PWM Timer Dead Time Value Register U

## GPT164 — General PWM 16-bit Timer 4
Base 0x40078400
Same registers: GPT165 0x40078500, GPT166 0x40078600, GPT167 0x40078700, GPT168 0x40078800, GPT169 0x40078900
Registers as GPT320; these are added or differ:
0x4C GTCCRA 32-bit reset 0xFFFF — General PWM Timer Compare Capture Register A
0x50 GTCCRB 32-bit reset 0xFFFF — General PWM Timer Compare Capture Register B
0x54 GTCCRC 32-bit reset 0xFFFF — General PWM Timer Compare Capture Register C
0x58 GTCCRE 32-bit reset 0xFFFF — General PWM Timer Compare Capture Register E
0x5C GTCCRD 32-bit reset 0xFFFF — General PWM Timer Compare Capture Register D
0x60 GTCCRF 32-bit reset 0xFFFF — General PWM Timer Compare Capture Register F
0x64 GTPR 32-bit reset 0xFFFF — General PWM Timer Cycle Setting Register
0x68 GTPBR 32-bit reset 0xFFFF — General PWM Timer Cycle Setting Buffer Register
0x8C GTDVU 32-bit reset 0xFFFF — General PWM Timer Dead Time Value Register U
